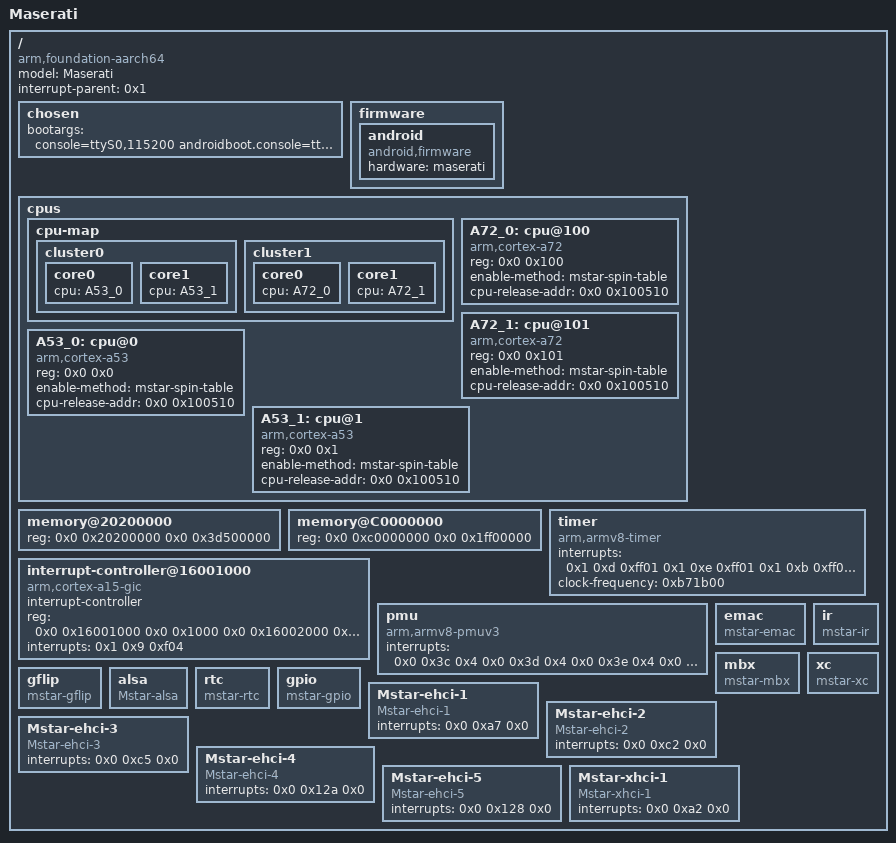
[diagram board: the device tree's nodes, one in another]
/dts-v1/;

/ {
	model = "Maserati";
	compatible = "arm,foundation-aarch64", "arm,maserati";
	interrupt-parent = <0x1>;
	#address-cells = <0x2>;
	#size-cells = <0x2>;

	chosen {
		bootargs = "console=ttyS0,115200 androidboot.console=ttyS0 root=/dev/ram rw rootwait init=/init CORE_DUMP_PATH=/data/core_dump.%%p.gz KDebug=1 delaylogo=true androidboot.selinux=permissive LX_MEM=0x3D500000 LX_MEM2=0xC0000000,0x1FF00000 EMAC_MEM=0x100000 PM51_ADDR=0x20010000 PM51_LEN=0x10000 CMA0=OTHERS,miu=0,hid=23,sz=0x7000000,st=0x11000000 CMA1=VDEC0,miu=0,hid=20,sz=0x3000000,st=0x18000000 CMA2=XC0,miu=0,hid=22,sz=0x6000000,st=0x1b000000 CMA3=OTHERS2,miu=1,hid=24,sz=0xec00000,st=0x0 CMA4=VDEC1,miu=1,hid=19,sz=0x7000000,st=0xec00000 CMA5=RETURN_ENUM,miu=1,hid=25,sz=0x2400000,st=0x15c00000 BOOTLOGO_IN_MBOOT ENV_VAR_OFFSET=0x0 ENV_VAR_SIZE=0x10000 ENV=EMMC SECURITY=ON";
	};

	firmware {

		android {
			compatible = "android,firmware";
			hardware = "maserati";
		};
	};

	cpus {
		#address-cells = <2>;
		#size-cells = <0>;

		cpu-map {
			cluster0: cluster0 {
			  #cooling-cells = <2>; /* min followed by max */
				core0 {
					cpu = <&A53_0>;
				};
				core1 {
					cpu = <&A53_1>;
				};
			};		
		
			cluster1: cluster1 {
        #cooling-cells = <2>; /* min followed by max */
				core0 {
					cpu = <&A72_0>;
				};
				core1 {
					cpu = <&A72_1>;
				};
			};
		};

		A72_0: cpu@100 {
			compatible = "arm,cortex-a72","arm,armv8";
			reg = <0x0 0x100>;
			device_type = "cpu";
			enable-method = "mstar-spin-table";
			cpu-release-addr = <0x0 0x100510>;			
		};

		A72_1: cpu@101 {
			compatible = "arm,cortex-a72","arm,armv8";
			reg = <0x0 0x101>;
			device_type = "cpu";
			enable-method = "mstar-spin-table";
			cpu-release-addr = <0x0 0x100510>;
		};

		A53_0: cpu@0 {
			compatible = "arm,cortex-a53","arm,armv8";
			reg = <0x0 0x0>;
			device_type = "cpu";
			enable-method = "mstar-spin-table";
			cpu-release-addr = <0x0 0x100510>;
		};

		A53_1: cpu@1 {
			compatible = "arm,cortex-a53","arm,armv8";
			reg = <0x0 0x1>;
			device_type = "cpu";
			enable-method = "mstar-spin-table";
			cpu-release-addr = <0x0 0x100510>;
		};
  };
		
	memory@20200000 {
		device_type = "memory";
		reg = <0x0 0x20200000 0x0 0x3d500000>;
	};

	memory@C0000000 {
		device_type = "memory";
		reg = <0x0 0xc0000000 0x0 0x1ff00000>;
	};

	interrupt-controller@16001000 {
		compatible = "arm,cortex-a15-gic", "arm,cortex-a9-gic";
		#interrupt-cells = <0x3>;
		#address-cells = <0x0>;
		interrupt-controller;
		reg = <0x0 0x16001000 0x0 0x1000 0x0 0x16002000 0x0 0x4000>;
		interrupts = <0x1 0x9 0xf04>;
		linux,phandle = <0x1>;
		phandle = <0x1>;
	};

	timer {
		compatible = "arm,armv8-timer";
		interrupts = <0x1 0xd 0xff01 0x1 0xe 0xff01 0x1 0xb 0xff01 0x1 0xa 0xff01>;
		clock-frequency = <0xb71b00>;
	};

	pmu {
		compatible = "arm,armv8-pmuv3";
		interrupts = <0x0 0x3c 0x4 0x0 0x3d 0x4 0x0 0x3e 0x4 0x0 0x3f 0x4>;
	};

	emac {
		compatible = "mstar-emac";
	};

	ir {
		compatible = "mstar-ir";
	};

	mbx {
		compatible = "mstar-mbx";
	};

	xc {
		compatible = "mstar-xc";
	};

	gflip {
		compatible = "mstar-gflip";
	};

	alsa {
		compatible = "Mstar-alsa";
	};

	rtc {
		compatible = "mstar-rtc";
	};

	gpio {
		compatible = "mstar-gpio";
	};

	Mstar-ehci-1 {
		compatible = "Mstar-ehci-1";
		interrupts = <0x0 0xa7 0x0>;
	};

	Mstar-ehci-2 {
		compatible = "Mstar-ehci-2";
		interrupts = <0x0 0xc2 0x0>;
	};

	Mstar-ehci-3 {
		compatible = "Mstar-ehci-3";
		interrupts = <0x0 0xc5 0x0>;
	};

	Mstar-ehci-4 {
		compatible = "Mstar-ehci-4";
		interrupts = <0x0 0x12a 0x0>;
	};

	Mstar-ehci-5 {
		compatible = "Mstar-ehci-5";
		interrupts = <0x0 0x128 0x0>;
	};

	Mstar-xhci-1 {
		compatible = "Mstar-xhci-1";
		interrupts = <0x0 0xa2 0x0>;
	};
};
